VERSION ""

NS_ :

BS_:

BU_: Pegasus Marvel Laptop Stark Xavier stark

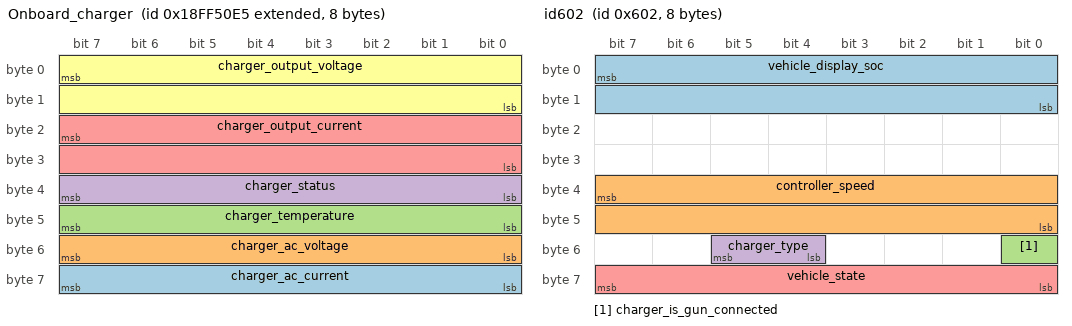
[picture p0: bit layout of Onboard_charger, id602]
BO_ 2566869221 Onboard_charger: 8 Vector__XXX
 SG_ charger_ac_current : 63|8@0+ (0.1,0) [0|255] "" Vector__XXX
 SG_ charger_ac_voltage : 55|8@0+ (1,0) [0|255] "" Vector__XXX
 SG_ charger_temperature : 47|8@0+ (1,0) [0|255] "" Vector__XXX
 SG_ charger_status : 39|8@0+ (1,0) [0|255] "" Vector__XXX
 SG_ charger_output_current : 23|16@0+ (0.1,0) [0|255] "" Vector__XXX
 SG_ charger_output_voltage : 7|16@0+ (0.1,0) [0|255] "" Vector__XXX

BO_ 2550588916 Stark_charger: 8 Vector__XXX
 SG_ charger_requested_current : 23|16@0+ (0.1,0) [0|255] "" Vector__XXX
 SG_ charger_requested_voltage : 7|16@0+ (0.1,0) [0|255] "" Vector__XXX

BO_ 1538 id602: 8 stark
 SG_ vehicle_display_soc : 7|16@0+ (0.1,0) [0|0] "" Vector__XXX
 SG_ controller_speed : 39|16@0+ (0.1,0) [0|65535] "" Vector__XXX
 SG_ charger_is_gun_connected : 48|1@1+ (1,0) [0|2] "" Vector__XXX
 SG_ charger_type : 52|2@1+ (1,0) [0|3] "" Vector__XXX
 SG_ vehicle_state : 63|8@0+ (1,0) [0|10] "" Vector__XXX

BO_ 1539 id603: 8 stark
 SG_ vehicle_calculated_odo : 23|32@0+ (0.01,0) [0|429496729.5] "Km" Vector__XXX

BO_ 1542 id606: 8 Vector__XXX
 SG_ vehicle_aux_charing_flag : 7|8@0+ (1,0) [0|3] "" Vector__XXX
 SG_ vehicle_aux_battery_voltage : 15|16@0+ (0.01,0) [0|655.35] "" Vector__XXX

BO_ 1541 id605: 8 Vector__XXX
 SG_ vehicle_stark_ticks : 7|32@0+ (1,0) [0|-1] "" Vector__XXX
 SG_ telemetry_start_index : 39|32@0+ (1,0) [0|-1] "" Vector__XXX

BO_ 1545 id609: 8 Vector__XXX
 SG_ vehicle_igni_debounce_count : 39|32@0+ (1,0) [0|-1] "" Vector__XXX
 SG_ vehicle_igni_cycle_count : 7|32@0+ (1,0) [0|-1] "" Vector__XXX

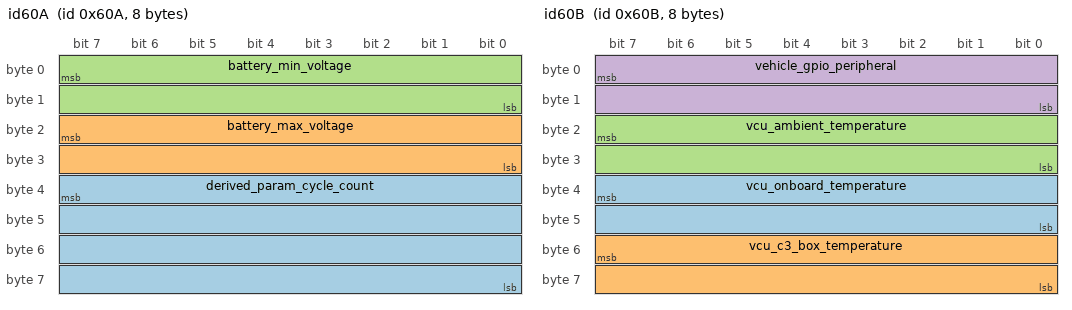
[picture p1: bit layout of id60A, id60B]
BO_ 1546 id60A: 8 Vector__XXX
 SG_ derived_param_cycle_count : 39|32@0+ (0.01,0) [0|-1] "" Vector__XXX
 SG_ battery_max_voltage : 23|16@0+ (0.1,0) [0|6553.5] "" Vector__XXX
 SG_ battery_min_voltage : 7|16@0+ (0.1,0) [0|6553.5] "" Vector__XXX

BO_ 1547 id60B: 8 Vector__XXX
 SG_ vcu_onboard_temperature : 39|16@0+ (0.1,0) [0|6553.5] "C" Vector__XXX
 SG_ vcu_c3_box_temperature : 55|16@0+ (0.1,0) [0|6553.5] "C" Vector__XXX
 SG_ vcu_ambient_temperature : 23|16@0+ (0.1,0) [0|6553.5] "C" Vector__XXX
 SG_ vehicle_gpio_peripheral : 7|16@0+ (1,0) [0|65535] "" Vector__XXX

BO_ 1548 id60C: 8 Vector__XXX
 SG_ vcu_uid1 : 7|64@0+ (1,0) [0|1.8446744074e+19] "" Vector__XXX

BO_ 1549 id60D: 8 Vector__XXX
 SG_ vcu_uid2 : 7|32@0+ (1,0) [0|-1] "" Vector__XXX

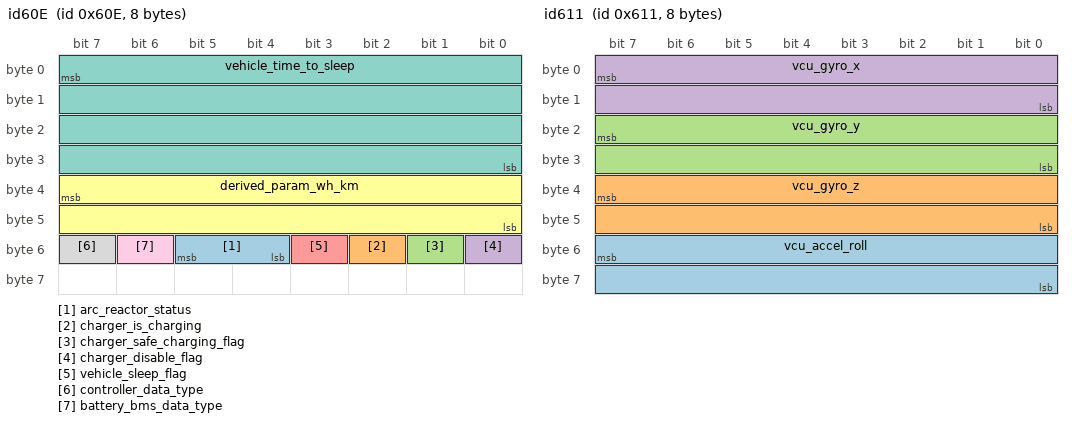
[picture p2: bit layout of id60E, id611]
BO_ 1550 id60E: 8 Vector__XXX
 SG_ arc_reactor_status : 52|2@1+ (1,0) [0|3] "" Vector__XXX
 SG_ charger_is_charging : 50|1@1+ (1,0) [0|1] "" Vector__XXX
 SG_ charger_safe_charging_flag : 49|1@1+ (1,0) [0|1] "" Vector__XXX
 SG_ charger_disable_flag : 48|1@1+ (1,0) [0|1] "" Vector__XXX
 SG_ vehicle_sleep_flag : 51|1@1+ (1,0) [0|1] "" Vector__XXX
 SG_ derived_param_wh_km : 39|16@0+ (0.1,0) [0|6553.5] "" Vector__XXX
 SG_ vehicle_time_to_sleep : 7|32@0+ (1,0) [0|-1] "" Vector__XXX
 SG_ controller_data_type : 55|1@1+ (1,0) [0|0] "" Vector__XXX
 SG_ battery_bms_data_type : 54|1@1+ (1,0) [0|0] "" Vector__XXX

BO_ 1552 id610: 8 Vector__XXX
 SG_ vehicle_ecu_manifest_crc : 39|32@0+ (1,0) [0|-1] "" Vector__XXX
 SG_ vehicle_manifest_crc : 7|32@0+ (1,0) [0|-1] "" Vector__XXX

BO_ 1553 id611: 8 Vector__XXX
 SG_ vcu_accel_roll : 55|16@0- (0.01,0) [-32768|32767] "" Vector__XXX
 SG_ vcu_gyro_z : 39|16@0- (0.01,0) [-32768|32767] "" Vector__XXX
 SG_ vcu_gyro_y : 23|16@0- (0.01,0) [-32768|32767] "" Vector__XXX
 SG_ vcu_gyro_x : 7|16@0- (0.01,0) [-327.68|327.67] "" Vector__XXX

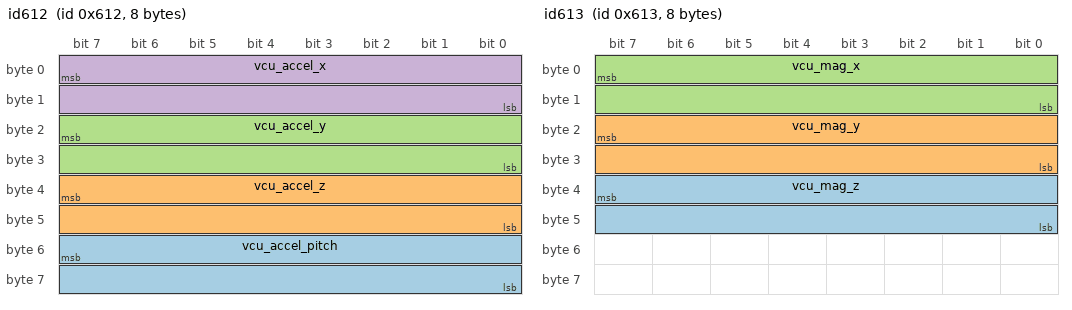
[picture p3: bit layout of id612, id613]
BO_ 1554 id612: 8 Vector__XXX
 SG_ vcu_accel_pitch : 55|16@0- (0.01,0) [-32768|32767] "" Vector__XXX
 SG_ vcu_accel_z : 39|16@0- (0.01,0) [-32768|32767] "" Vector__XXX
 SG_ vcu_accel_y : 23|16@0- (0.01,0) [-32768|32767] "" Vector__XXX
 SG_ vcu_accel_x : 7|16@0- (0.01,0) [-327.68|327.67] "" Vector__XXX

BO_ 1555 id613: 8 Vector__XXX
 SG_ vcu_mag_z : 39|16@0- (0.1,0) [-32768|32767] "" Vector__XXX
 SG_ vcu_mag_y : 23|16@0- (0.1,0) [-32768|32767] "" Vector__XXX
 SG_ vcu_mag_x : 7|16@0- (0.1,0) [-327.68|327.67] "" Vector__XXX

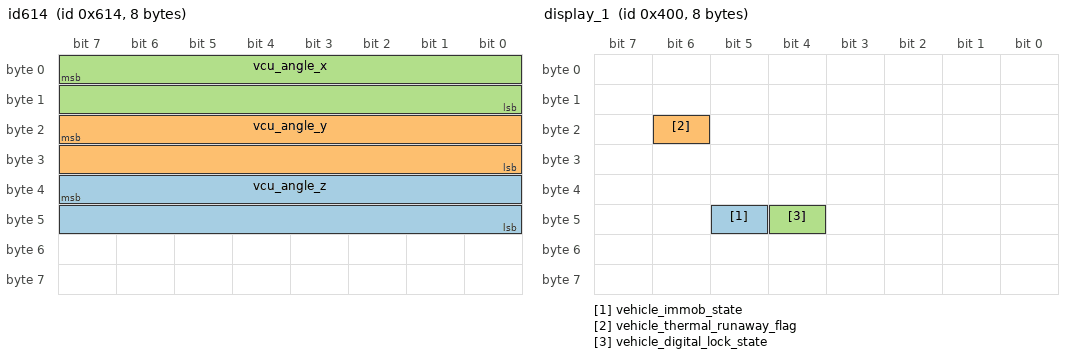
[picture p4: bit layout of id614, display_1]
BO_ 1556 id614: 8 Vector__XXX
 SG_ vcu_angle_z : 39|16@0- (0.1,0) [-32768|32767] "" Vector__XXX
 SG_ vcu_angle_y : 23|16@0- (0.1,0) [-32768|32767] "" Vector__XXX
 SG_ vcu_angle_x : 7|16@0- (0.1,0) [-327.68|327.67] "" Vector__XXX

BO_ 1557 id615: 8 Vector__XXX
 SG_ error_1 : 7|64@0+ (1,0) [-32768|32767] "" Vector__XXX

BO_ 1558 id616: 8 Vector__XXX
 SG_ error_2 : 7|32@0+ (1,0) [-32768|32767] "" Vector__XXX
 SG_ unknown_error_1 : 39|16@0+ (1,0) [-32768|32767] "" Vector__XXX
 SG_ unknown_error_2 : 55|16@0+ (1,0) [-327.68|327.67] "" Vector__XXX

BO_ 1559 id617: 8 Vector__XXX
 SG_ controller_error : 7|64@0+ (1,0) [0|0] "" Vector__XXX

BO_ 1026 display_3: 8 Stark
 SG_ vehicle_calculated_trip : 32|32@1+ (0.1,0) [0|0] ""  Xavier

BO_ 1025 display_2: 8 Stark
 SG_ vehicle_ttfc : 32|16@1+ (1,0) [0|0] ""  Xavier
 SG_ vehicle_range : 16|16@1+ (0.1,0) [0|0] ""  Xavier

BO_ 1024 display_1: 8 Stark
 SG_ vehicle_immob_state : 45|1@1+ (1,0) [0|1] "" Vector__XXX
 SG_ vehicle_thermal_runaway_flag : 22|1@1+ (1,0) [0|1] "" Vector__XXX
 SG_ vehicle_digital_lock_state : 44|1@1+ (1,0) [0|1] "" Vector__XXX

BO_ 1969 GetGITSHA: 8 Xavier
 SG_ git_shaw : 16|32@1+ (1,0) [0|-1] ""  Laptop
 SG_ device_id : 0|8@1+ (1,0) [0|255] ""  Laptop

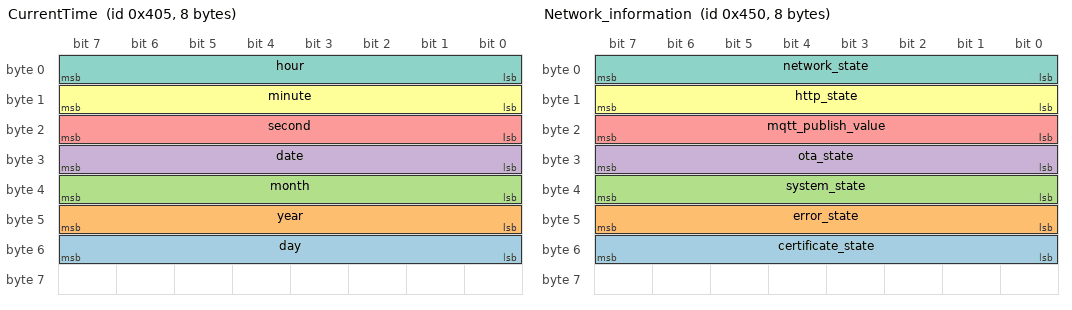
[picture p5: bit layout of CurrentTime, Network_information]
BO_ 1029 CurrentTime: 8 Xavier
 SG_ day : 48|8@1+ (1,0) [0|255] ""  Laptop,Stark
 SG_ year : 40|8@1+ (1,0) [0|255] ""  Laptop,Stark
 SG_ month : 32|8@1+ (1,0) [0|255] ""  Laptop,Stark
 SG_ date : 24|8@1+ (1,0) [0|255] ""  Laptop,Stark
 SG_ second : 16|8@1+ (1,0) [0|255] ""  Laptop,Stark
 SG_ minute : 8|8@1+ (1,0) [0|255] ""  Laptop,Stark
 SG_ hour : 0|8@1+ (1,0) [0|255] ""  Laptop,Stark

BO_ 1783 sim_number_16_20: 8 Xavier
 SG_ sim_16_20 : 0|32@1+ (1,0) [0|-1] ""  Laptop

BO_ 1782 sim_number_0_16: 8 Xavier
 SG_ sim_0_16 : 0|64@1+ (1,0) [0|9.2233720369e+18] ""  Laptop

BO_ 1779 xavier_1: 8 Xavier
 SG_ imei : 0|64@1+ (1,0) [0|9.2233720369e+18] ""  Laptop

BO_ 1104 Network_information: 8 Xavier
 SG_ certificate_state : 48|8@1+ (1,0) [0|255] ""  Laptop
 SG_ error_state : 40|8@1+ (1,0) [0|255] ""  Laptop
 SG_ system_state : 32|8@1+ (1,0) [0|255] ""  Laptop
 SG_ ota_state : 24|8@1+ (1,0) [0|255] ""  Laptop
 SG_ mqtt_publish_value : 16|8@1+ (1,0) [0|255] ""  Laptop
 SG_ http_state : 8|8@1+ (1,0) [0|255] ""  Laptop
 SG_ network_state : 0|8@1+ (1,0) [0|0] ""  Laptop

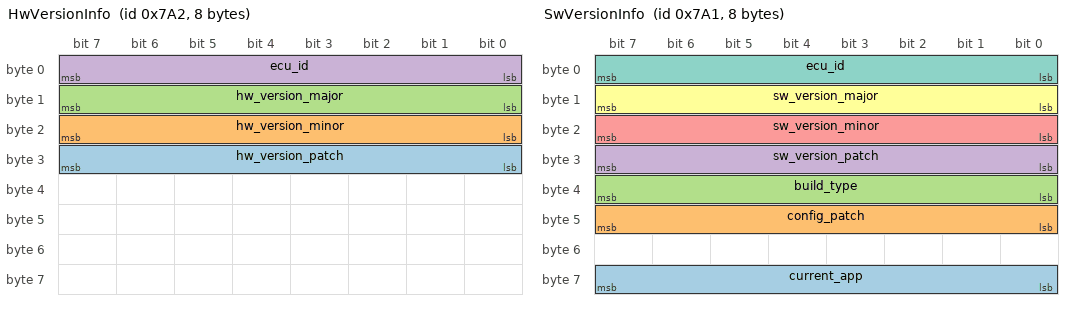
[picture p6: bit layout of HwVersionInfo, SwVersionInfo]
BO_ 1954 HwVersionInfo: 8 Xavier
 SG_ hw_version_patch : 24|8@1+ (1,0) [0|255] ""  Laptop,Stark
 SG_ hw_version_minor : 16|8@1+ (1,0) [0|255] ""  Laptop,Stark
 SG_ hw_version_major : 8|8@1+ (1,0) [0|255] ""  Laptop,Stark
 SG_ ecu_id : 0|8@1+ (1,0) [0|255] ""  Stark,Laptop

BO_ 1953 SwVersionInfo: 8 Xavier
 SG_ current_app : 56|8@1+ (1,0) [0|255] ""  Laptop,Stark
 SG_ config_patch : 40|8@1+ (1,0) [0|255] ""  Laptop,Stark
 SG_ build_type : 32|8@1+ (1,0) [0|255] ""  Laptop,Stark
 SG_ sw_version_patch : 24|8@1+ (1,0) [0|255] ""  Laptop,Stark
 SG_ sw_version_minor : 16|8@1+ (1,0) [0|255] ""  Laptop,Stark
 SG_ sw_version_major : 8|8@1+ (1,0) [0|255] ""  Laptop,Stark
 SG_ ecu_id : 0|8@1+ (1,0) [0|255] ""  Laptop,Stark

BO_ 600 bms_258: 8 Vector__XXX
 SG_ battery_active_errors_count : 39|16@0+ (1,0) [0|65535] "Value" Vector__XXX

BO_ 601 bms_259: 8 Vector__XXX
 SG_ battery_bms_errors_since_boot : 39|32@0+ (1,0) [0|255] "" Vector__XXX

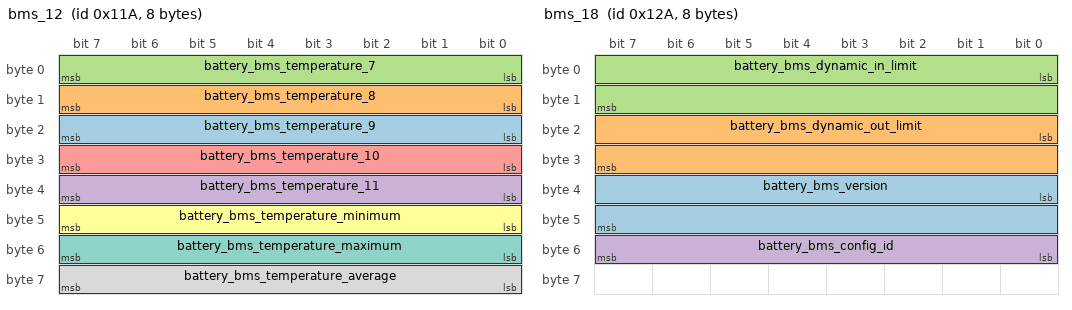
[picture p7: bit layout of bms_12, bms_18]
BO_ 282 bms_12: 8 Vector__XXX
 SG_ battery_bms_temperature_9 : 16|8@1+ (1,0) [0|255] "C" Vector__XXX
 SG_ battery_bms_temperature_8 : 8|8@1+ (1,0) [0|255] "C" Vector__XXX
 SG_ battery_bms_temperature_7 : 0|8@1+ (1,0) [0|255] "C" Vector__XXX
 SG_ battery_bms_temperature_11 : 32|8@1+ (1,0) [0|255] "C" Vector__XXX
 SG_ battery_bms_temperature_10 : 24|8@1+ (1,0) [0|255] "C" Vector__XXX
 SG_ battery_bms_temperature_minimum : 40|8@1- (1,0) [-40|125] "C" Vector__XXX
 SG_ battery_bms_temperature_maximum : 48|8@1- (1,0) [-40|125] "C" Vector__XXX
 SG_ battery_bms_temperature_average : 56|8@1- (1,0) [-40|125] "C" Vector__XXX

BO_ 284 bms_13: 8 Vector__XXX
 SG_ battery_bms_max_capacity : 0|16@1+ (0.1,0) [0|6553.5] "Ah" Vector__XXX
 SG_ battery_cmu_2_balancing_mask : 48|16@1+ (1,0) [0|65535] "" Vector__XXX
 SG_ battery_cmu_1_balancing_mask : 32|16@1+ (1,0) [0|65535] "" Vector__XXX

BO_ 299 bms_19: 8 Vector__XXX
 SG_ battery_cmu_3_balancing_mask : 48|16@1+ (1,0) [0|65535] "" Vector__XXX

BO_ 298 bms_18: 8 Vector__XXX
 SG_ battery_bms_version : 32|16@1+ (1,0) [0|65535] "" Vector__XXX
 SG_ battery_bms_dynamic_out_limit : 16|16@1- (0.1,0) [-3276.8|3276.7] "A" Vector__XXX
 SG_ battery_bms_dynamic_in_limit : 0|16@1- (0.1,0) [-3276.8|3276.7] "A" Vector__XXX
 SG_ battery_bms_config_id : 48|8@1- (1,0) [-128|127] "" Vector__XXX

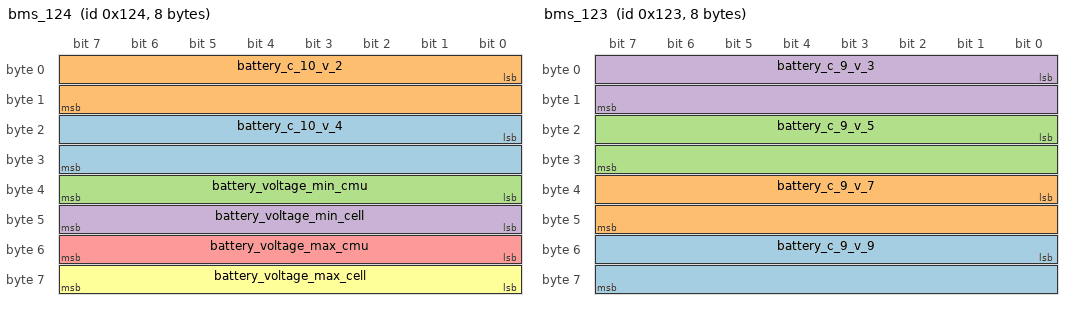
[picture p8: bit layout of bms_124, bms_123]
BO_ 292 bms_124: 8 Vector__XXX
 SG_ battery_c_10_v_4 : 16|16@1+ (0.1,0) [0|6553.5] "mV" Vector__XXX
 SG_ battery_c_10_v_2 : 0|16@1+ (0.1,0) [0|6553.5] "mV" Vector__XXX
 SG_ battery_voltage_min_cmu : 32|8@1+ (1,0) [0|255] "" Vector__XXX
 SG_ battery_voltage_min_cell : 40|8@1+ (1,0) [0|255] "" Vector__XXX
 SG_ battery_voltage_max_cmu : 48|8@1+ (1,0) [0|255] "" Vector__XXX
 SG_ battery_voltage_max_cell : 56|8@1+ (1,0) [0|255] "" Vector__XXX

BO_ 291 bms_123: 8 Vector__XXX
 SG_ battery_c_9_v_9 : 48|16@1+ (0.1,0) [0|6553.5] "mV" Vector__XXX
 SG_ battery_c_9_v_7 : 32|16@1+ (0.1,0) [0|6553.5] "mV" Vector__XXX
 SG_ battery_c_9_v_5 : 16|16@1+ (0.1,0) [0|6553.5] "mV" Vector__XXX
 SG_ battery_c_9_v_3 : 0|16@1+ (0.1,0) [0|6553.5] "mV" Vector__XXX

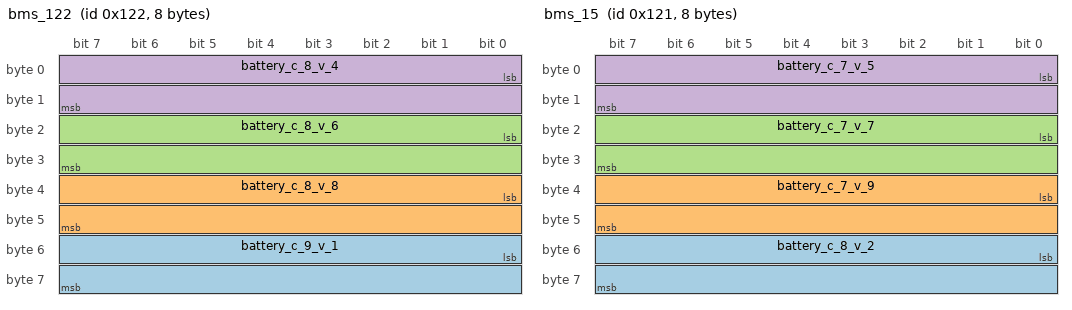
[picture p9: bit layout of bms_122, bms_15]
BO_ 290 bms_122: 8 Vector__XXX
 SG_ battery_c_9_v_1 : 48|16@1+ (0.1,0) [0|6553.5] "mV" Vector__XXX
 SG_ battery_c_8_v_8 : 32|16@1+ (0.1,0) [0|6553.5] "mV" Vector__XXX
 SG_ battery_c_8_v_6 : 16|16@1+ (0.1,0) [0|6553.5] "mV" Vector__XXX
 SG_ battery_c_8_v_4 : 0|16@1+ (0.1,0) [0|6553.5] "mV" Vector__XXX

BO_ 289 bms_15: 8 Vector__XXX
 SG_ battery_c_8_v_2 : 48|16@1+ (0.1,0) [0|6553.5] "mV" Vector__XXX
 SG_ battery_c_7_v_9 : 32|16@1+ (0.1,0) [0|6553.5] "mV" Vector__XXX
 SG_ battery_c_7_v_7 : 16|16@1+ (0.1,0) [0|6553.5] "mV" Vector__XXX
 SG_ battery_c_7_v_5 : 0|16@1+ (0.1,0) [0|6553.5] "mV" Vector__XXX

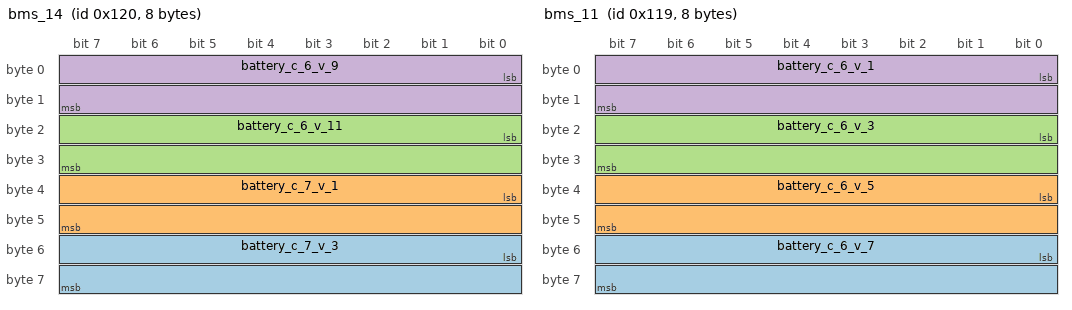
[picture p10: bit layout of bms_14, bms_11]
BO_ 288 bms_14: 8 Vector__XXX
 SG_ battery_c_7_v_3 : 48|16@1+ (0.1,0) [0|6553.5] "mV" Vector__XXX
 SG_ battery_c_7_v_1 : 32|16@1+ (0.1,0) [0|6553.5] "mV" Vector__XXX
 SG_ battery_c_6_v_11 : 16|16@1+ (0.1,0) [0|6553.5] "mV" Vector__XXX
 SG_ battery_c_6_v_9 : 0|16@1+ (0.1,0) [0|6553.5] "mV" Vector__XXX

BO_ 281 bms_11: 8 Vector__XXX
 SG_ battery_c_6_v_7 : 48|16@1+ (0.1,0) [0|6553.5] "mV" Vector__XXX
 SG_ battery_c_6_v_5 : 32|16@1+ (0.1,0) [0|6553.5] "mV" Vector__XXX
 SG_ battery_c_6_v_3 : 16|16@1+ (0.1,0) [0|6553.5] "mV" Vector__XXX
 SG_ battery_c_6_v_1 : 0|16@1+ (0.1,0) [0|6553.5] "mV" Vector__XXX

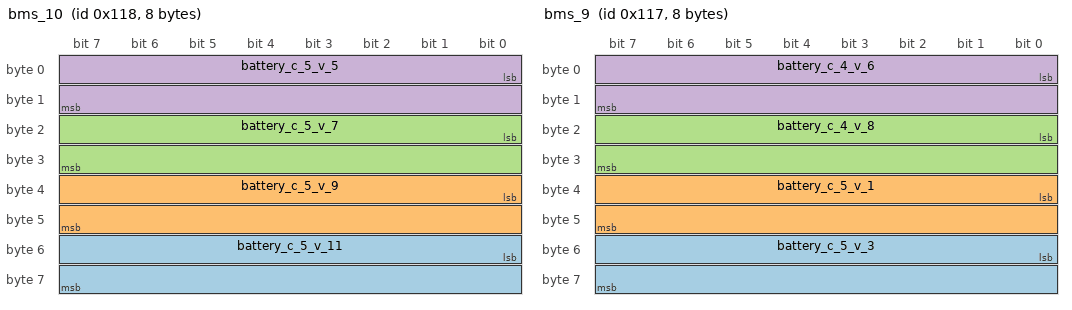
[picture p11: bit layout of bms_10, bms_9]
BO_ 280 bms_10: 8 Vector__XXX
 SG_ battery_c_5_v_11 : 48|16@1+ (0.1,0) [0|6553.5] "mV" Vector__XXX
 SG_ battery_c_5_v_9 : 32|16@1+ (0.1,0) [0|6553.5] "mV" Vector__XXX
 SG_ battery_c_5_v_7 : 16|16@1+ (0.1,0) [0|6553.5] "mV" Vector__XXX
 SG_ battery_c_5_v_5 : 0|16@1+ (0.1,0) [0|6553.5] "mV" Vector__XXX

BO_ 279 bms_9: 8 Vector__XXX
 SG_ battery_c_5_v_3 : 48|16@1+ (0.1,0) [0|6553.5] "mV" Vector__XXX
 SG_ battery_c_5_v_1 : 32|16@1+ (0.1,0) [0|6553.5] "mV" Vector__XXX
 SG_ battery_c_4_v_8 : 16|16@1+ (0.1,0) [0|6553.5] "mV" Vector__XXX
 SG_ battery_c_4_v_6 : 0|16@1+ (0.1,0) [0|6553.5] "mV" Vector__XXX

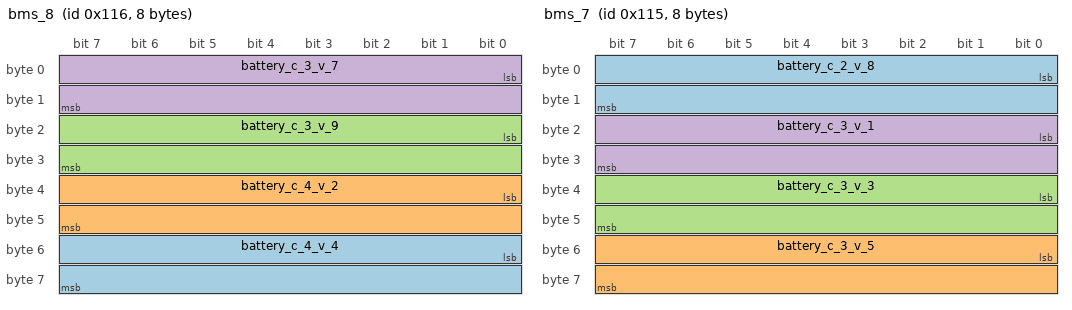
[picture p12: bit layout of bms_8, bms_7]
BO_ 278 bms_8: 8 Vector__XXX
 SG_ battery_c_4_v_4 : 48|16@1+ (0.1,0) [0|6553.5] "mV" Vector__XXX
 SG_ battery_c_4_v_2 : 32|16@1+ (0.1,0) [0|6553.5] "mV" Vector__XXX
 SG_ battery_c_3_v_9 : 16|16@1+ (0.1,0) [0|6553.5] "mV" Vector__XXX
 SG_ battery_c_3_v_7 : 0|16@1+ (0.1,0) [0|6553.5] "mV" Vector__XXX

BO_ 277 bms_7: 8 Vector__XXX
 SG_ battery_c_2_v_8 : 0|16@1+ (0.1,0) [0|6553.5] "mV" Vector__XXX
 SG_ battery_c_3_v_5 : 48|16@1+ (0.1,0) [0|6553.5] "mV" Vector__XXX
 SG_ battery_c_3_v_3 : 32|16@1+ (0.1,0) [0|6553.5] "mV" Vector__XXX
 SG_ battery_c_3_v_1 : 16|16@1+ (0.1,0) [0|6553.5] "mV" Vector__XXX

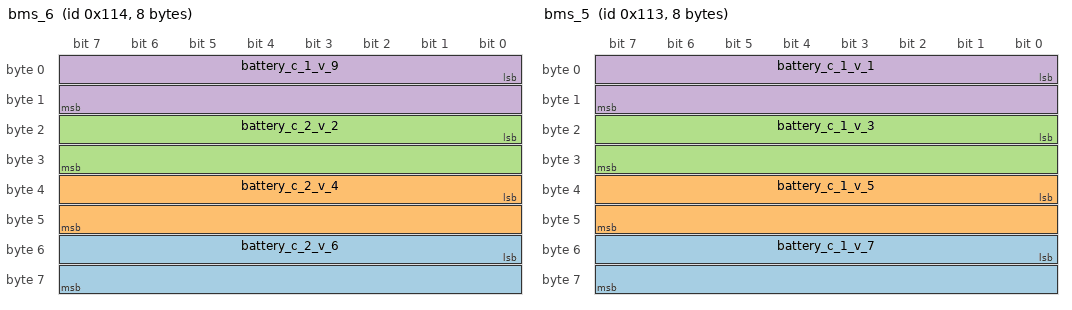
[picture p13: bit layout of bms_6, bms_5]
BO_ 276 bms_6: 8 Vector__XXX
 SG_ battery_c_2_v_6 : 48|16@1+ (0.1,0) [0|6553.5] "mV" Vector__XXX
 SG_ battery_c_2_v_4 : 32|16@1+ (0.1,0) [0|6553.5] "mV" Vector__XXX
 SG_ battery_c_2_v_2 : 16|16@1+ (0.1,0) [0|6553.5] "mV" Vector__XXX
 SG_ battery_c_1_v_9 : 0|16@1+ (0.1,0) [0|6553.5] "mV" Vector__XXX

BO_ 275 bms_5: 8 Vector__XXX
 SG_ battery_c_1_v_7 : 48|16@1+ (0.1,0) [0|6553.5] "mV" Vector__XXX
 SG_ battery_c_1_v_5 : 32|16@1+ (0.1,0) [0|6553.5] "mV" Vector__XXX
 SG_ battery_c_1_v_3 : 16|16@1+ (0.1,0) [0|6553.5] "mV" Vector__XXX
 SG_ battery_c_1_v_1 : 0|16@1+ (0.1,0) [0|6553.5] "mV" Vector__XXX

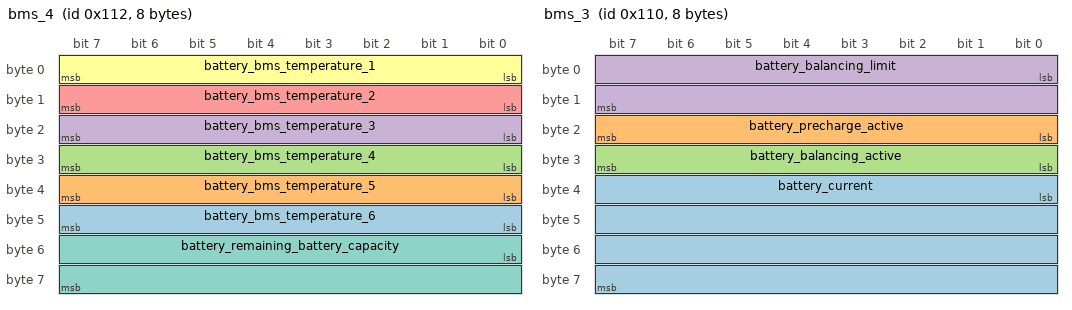
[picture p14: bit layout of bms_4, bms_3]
BO_ 274 bms_4: 8 Vector__XXX
 SG_ battery_bms_temperature_6 : 40|8@1+ (1,0) [0|255] "C" Vector__XXX
 SG_ battery_bms_temperature_5 : 32|8@1+ (1,0) [0|255] "C" Vector__XXX
 SG_ battery_bms_temperature_4 : 24|8@1+ (1,0) [0|255] "C" Vector__XXX
 SG_ battery_bms_temperature_3 : 16|8@1+ (1,0) [0|255] "C" Vector__XXX
 SG_ battery_bms_temperature_2 : 8|8@1+ (1,0) [0|255] "C" Vector__XXX
 SG_ battery_bms_temperature_1 : 0|8@1+ (1,0) [0|255] "C" Vector__XXX
 SG_ battery_remaining_battery_capacity : 48|16@1- (0.1,0) [0|6553.5] "Ah" Vector__XXX

BO_ 272 bms_3: 8 Vector__XXX
 SG_ battery_current : 32|32@1- (1e-05,0) [-21474836.48|21474836.47] "A" Vector__XXX
 SG_ battery_precharge_active : 16|8@1+ (1,0) [0|255] "" Vector__XXX
 SG_ battery_balancing_active : 24|8@1+ (1,0) [0|255] "" Vector__XXX
 SG_ battery_balancing_limit : 0|16@1+ (0.1,0) [0|65535] "mV" Vector__XXX

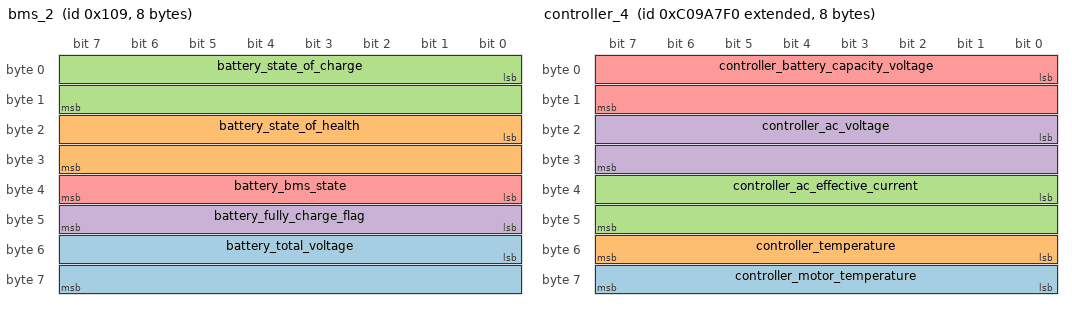
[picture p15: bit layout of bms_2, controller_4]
BO_ 265 bms_2: 8 Marvel
 SG_ battery_total_voltage : 48|16@1+ (0.1,0) [0|6553.5] "V" Vector__XXX
 SG_ battery_state_of_health : 16|16@1+ (0.01,0) [0|655.35] "%" Vector__XXX
 SG_ battery_state_of_charge : 0|16@1+ (0.01,0) [0|655.35] "%" Vector__XXX
 SG_ battery_fully_charge_flag : 40|8@1+ (1,0) [0|255] "" Vector__XXX
 SG_ battery_bms_state : 32|8@1+ (1,0) [0|255] "" Vector__XXX

BO_ 263 bms_0: 8 Marvel
 SG_ battery_bms_requested_voltage : 7|16@0+ (0.1,0) [0|65535] "V" Vector__XXX
 SG_ battery_bms_requested_current : 23|16@0+ (0.1,0) [0|6553.5] "" Vector__XXX

BO_ 1798 controller_0: 8 Vector__XXX
 SG_ controller_regen_off : 10|1@1+ (1,0) [0|0] "" Vector__XXX

BO_ 1830 controller_2: 8 Vector__XXX
 SG_ controller_config_version : 0|8@1+ (1,0) [0|0] "" Vector__XXX
 SG_ controller_serial_number : 8|24@1+ (1,0) [0|0] "" Vector__XXX
 SG_ controller_os_version : 56|8@1+ (1,0) [0|0] "" Vector__XXX

BO_ 1829 controller_1: 2 Vector__XXX
 SG_ controller_brake_pot : 8|8@1+ (0.1,0) [0|0] "V" Vector__XXX
 SG_ controller_brake_command : 0|8@1+ (1,0) [0|0] "%" Vector__XXX

BO_ 2349508592 controller_5: 8 Vector__XXX
 SG_ controller_error_count : 56|3@1+ (1,0) [0|0] "" Vector__XXX
 SG_ controller_brake_status : 62|1@1+ (1,0) [0|0] "" Vector__XXX

BO_ 2349443056 controller_4: 8 Vector__XXX
 SG_ controller_motor_temperature : 56|8@1+ (1,-40) [0|0] "  C" Vector__XXX
 SG_ controller_temperature : 48|8@1+ (1,-40) [0|0] "  C" Vector__XXX
 SG_ controller_ac_effective_current : 32|16@1+ (0.1,-3200) [0|0] "A" Vector__XXX
 SG_ controller_ac_voltage : 16|16@1+ (0.1,0) [0|0] "V" Vector__XXX
 SG_ controller_battery_capacity_voltage : 0|16@1+ (0.1,0) [0|0] "V" Vector__XXX

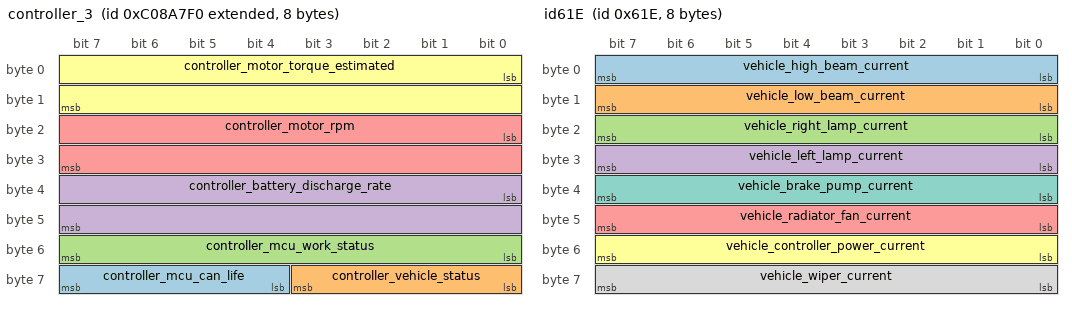
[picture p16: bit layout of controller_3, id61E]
BO_ 2349377520 controller_3: 8 Vector__XXX
 SG_ controller_mcu_can_life : 60|4@1+ (1,0) [0|0] "" Vector__XXX
 SG_ controller_vehicle_status : 56|4@1+ (1,0) [0|0] "" Vector__XXX
 SG_ controller_mcu_work_status : 48|8@1+ (1,0) [0|0] "" Vector__XXX
 SG_ controller_battery_discharge_rate : 32|16@1+ (0.1,-3200) [0|0] "A" Vector__XXX
 SG_ controller_motor_rpm : 16|16@1+ (1,-32000) [0|0] "rpm" Vector__XXX
 SG_ controller_motor_torque_estimated : 0|16@1+ (0.1,-3200) [0|0] "Nm" Vector__XXX

BO_ 1566 id61E: 8 Vector__XXX
 SG_ vehicle_high_beam_current : 7|8@0+ (0.1,0) [0|0] "" Vector__XXX
 SG_ vehicle_low_beam_current : 15|8@0+ (0.1,0) [0|0] "" Vector__XXX
 SG_ vehicle_right_lamp_current : 23|8@0+ (0.1,0) [0|0] "" Vector__XXX
 SG_ vehicle_left_lamp_current : 31|8@0+ (0.1,0) [0|0] "" Vector__XXX
 SG_ vehicle_radiator_fan_current : 47|8@0+ (0.1,0) [0|0] "" Vector__XXX
 SG_ vehicle_controller_power_current : 55|8@0+ (0.1,0) [0|0] "" Vector__XXX
 SG_ vehicle_brake_pump_current : 39|8@0+ (0.1,0) [0|0] "" Vector__XXX
 SG_ vehicle_wiper_current : 63|8@0+ (0.1,0) [0|0] "" Vector__XXX

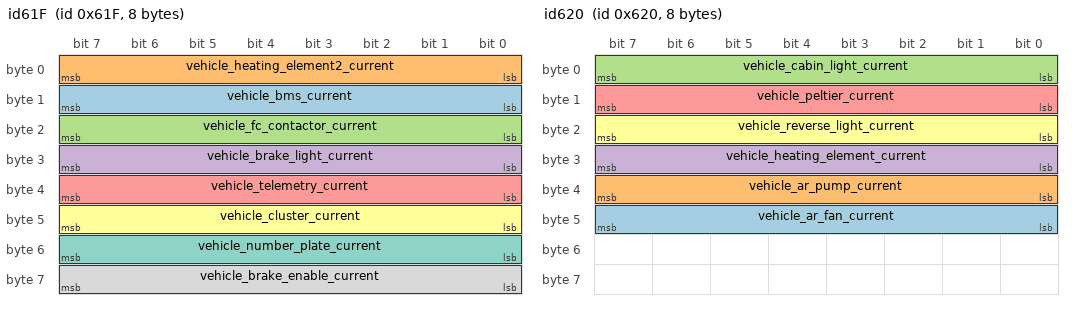
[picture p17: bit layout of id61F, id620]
BO_ 1567 id61F: 8 Vector__XXX
 SG_ vehicle_bms_current : 15|8@0+ (0.01,0) [0|0] "" Vector__XXX
 SG_ vehicle_heating_element2_current : 7|8@0+ (0.1,0) [0|0] "" Vector__XXX
 SG_ vehicle_fc_contactor_current : 23|8@0+ (0.1,0) [0|0] "" Vector__XXX
 SG_ vehicle_brake_light_current : 31|8@0+ (0.1,0) [0|0] "" Vector__XXX
 SG_ vehicle_telemetry_current : 39|8@0+ (0.01,0) [0|0] "" Vector__XXX
 SG_ vehicle_cluster_current : 47|8@0+ (0.01,0) [0|0] "" Vector__XXX
 SG_ vehicle_number_plate_current : 55|8@0+ (0.1,0) [0|0] "" Vector__XXX
 SG_ vehicle_brake_enable_current : 63|8@0+ (0.1,0) [0|0] "" Vector__XXX

BO_ 1568 id620: 8 Vector__XXX
 SG_ vehicle_ar_fan_current : 47|8@0+ (0.1,0) [0|0] "" Vector__XXX
 SG_ vehicle_ar_pump_current : 39|8@0+ (0.1,0) [0|0] "" Vector__XXX
 SG_ vehicle_cabin_light_current : 7|8@0+ (0.1,0) [0|0] "" Vector__XXX
 SG_ vehicle_heating_element_current : 31|8@0+ (0.1,0) [0|0] "" Vector__XXX
 SG_ vehicle_peltier_current : 15|8@0+ (0.1,0) [0|0] "" Vector__XXX
 SG_ vehicle_reverse_light_current : 23|8@0+ (0.1,0) [0|0] "" Vector__XXX

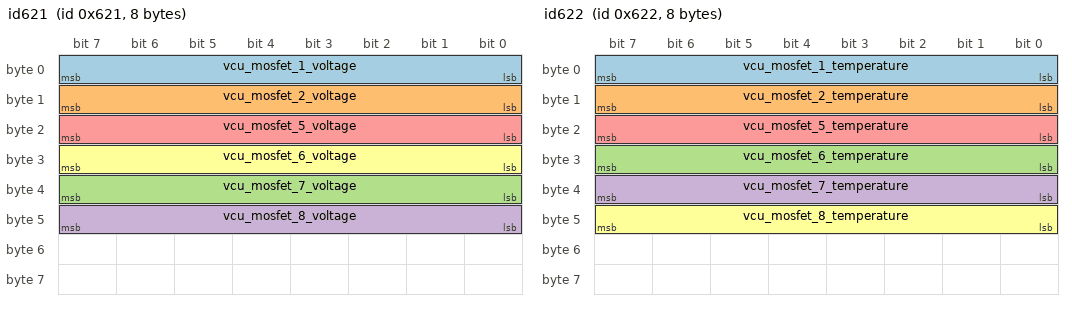
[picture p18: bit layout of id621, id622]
BO_ 1569 id621: 8 Vector__XXX
 SG_ vcu_mosfet_1_voltage : 7|8@0+ (0.1,0) [0|0] "" Vector__XXX
 SG_ vcu_mosfet_2_voltage : 15|8@0+ (0.1,0) [0|0] "" Vector__XXX
 SG_ vcu_mosfet_7_voltage : 39|8@0+ (0.1,0) [0|0] "" Vector__XXX
 SG_ vcu_mosfet_8_voltage : 47|8@0+ (0.1,0) [0|0] "" Vector__XXX
 SG_ vcu_mosfet_5_voltage : 23|8@0+ (0.1,0) [0|0] "" Vector__XXX
 SG_ vcu_mosfet_6_voltage : 31|8@0+ (0.1,0) [0|0] "" Vector__XXX

BO_ 1570 id622: 8 Vector__XXX
 SG_ vcu_mosfet_1_temperature : 7|8@0+ (1,0) [0|0] "" Vector__XXX
 SG_ vcu_mosfet_2_temperature : 15|8@0+ (1,0) [0|0] "" Vector__XXX
 SG_ vcu_mosfet_6_temperature : 31|8@0+ (1,0) [0|0] "" Vector__XXX
 SG_ vcu_mosfet_7_temperature : 39|8@0+ (1,0) [0|0] "" Vector__XXX
 SG_ vcu_mosfet_5_temperature : 23|8@0+ (1,0) [0|0] "" Vector__XXX
 SG_ vcu_mosfet_8_temperature : 47|8@0+ (1,0) [0|0] "" Vector__XXX

BO_ 1571 id623: 8 Vector__XXX
 SG_ vehicle_gpio_peripheral2 : 7|16@0+ (1,0) [0|0] "" Vector__XXX
 SG_ vcu_mcu_reference_voltage : 47|16@0+ (1,0) [0|0] "" Vector__XXX

BO_ 1562 id61A: 8 Vector__XXX
 SG_ vcu_high_current_flag : 39|32@0+ (1,0) [0|0] "" Vector__XXX
 SG_ vcu_short_circuit_flag : 7|32@0+ (1,0) [0|0] "" Vector__XXX

BO_ 1563 id61B: 8 Vector__XXX
 SG_ vcu_over_temp_flag : 39|32@0+ (1,0) [0|0] "" Vector__XXX
 SG_ vcu_under_voltage_flag : 7|32@0+ (1,0) [0|0] "" Vector__XXX

BO_ 1564 id61C: 8 Vector__XXX
 SG_ vcu_open_circuit_flag : 39|32@0+ (1,0) [0|0] "" Vector__XXX
 SG_ vcu_peripheral_failure_flag : 7|32@0+ (1,0) [0|0] "" Vector__XXX

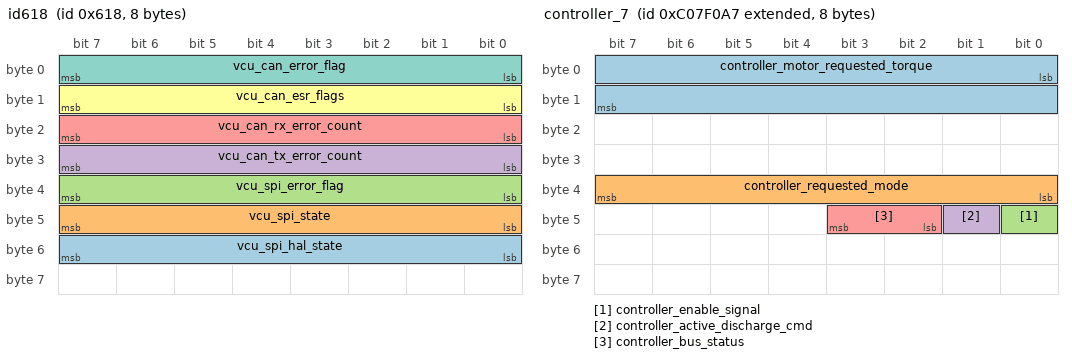
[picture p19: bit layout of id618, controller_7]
BO_ 1560 id618: 8 Stark
 SG_ vcu_spi_hal_state : 55|8@0+ (1,0) [0|255] "" Vector__XXX
 SG_ vcu_spi_state : 47|8@0+ (1,0) [0|255] "" Vector__XXX
 SG_ vcu_spi_error_flag : 39|8@0+ (1,0) [0|255] "" Vector__XXX
 SG_ vcu_can_tx_error_count : 31|8@0+ (1,0) [0|255] "" Vector__XXX
 SG_ vcu_can_rx_error_count : 23|8@0+ (1,0) [0|255] "" Vector__XXX
 SG_ vcu_can_esr_flags : 15|8@0+ (1,0) [0|255] "" Vector__XXX
 SG_ vcu_can_error_flag : 7|8@0+ (1,0) [0|255] "" Vector__XXX

BO_ 1808 controller_6: 8 Vector__XXX
 SG_ controller_throttle_command : 0|8@1+ (1,0) [0|100] "%" Vector__XXX
 SG_ controller_throttle_potentiometer : 24|8@1+ (0.1,0) [0|10] "V" Vector__XXX

BO_ 2349330599 controller_7: 8 Vector__XXX
 SG_ controller_motor_requested_torque : 0|16@1+ (0.1,-3200) [0|0] "Nm" Vector__XXX
 SG_ controller_requested_mode : 32|8@1+ (1,0) [0|0] "" Vector__XXX
 SG_ controller_enable_signal : 40|1@1+ (1,0) [0|0] "" Vector__XXX
 SG_ controller_active_discharge_cmd : 41|1@1+ (1,0) [0|0] "" Vector__XXX
 SG_ controller_bus_status : 42|2@1+ (1,0) [0|0] "" Vector__XXX

CM_ SG_ 1798 controller_regen_off "   ռ    ־";
CM_ SG_ 1830 controller_config_version "   ð汾";
CM_ SG_ 1829 controller_brake_pot "ɲ    ѹ";
CM_ SG_ 1829 controller_brake_command "ɲ   ٷֱ ";
CM_ SG_ 2349443056 controller_motor_temperature "    ¶ ";
CM_ SG_ 2349443056 controller_temperature "          ¶ ";
CM_ SG_ 2349443056 controller_ac_effective_current "      Чֵ";
CM_ SG_ 2349443056 controller_ac_voltage "MCU      ѹ";
CM_ SG_ 2349443056 controller_battery_capacity_voltage "MCUֱ    ѹ";
CM_ SG_ 2349377520 controller_vehicle_status "MCU  ǰ  λ";
CM_ SG_ 2349377520 controller_battery_discharge_rate "ֱ  ĸ ߵ   ";
CM_ SG_ 2349377520 controller_motor_rpm "   ʵ  ת  ";
CM_ SG_ 2349377520 controller_motor_torque_estimated "      Ť  ";
VAL_ 2349377520 controller_vehicle_status 3 "Brake" 2 "R" 1 "D" 0 "N" ;
